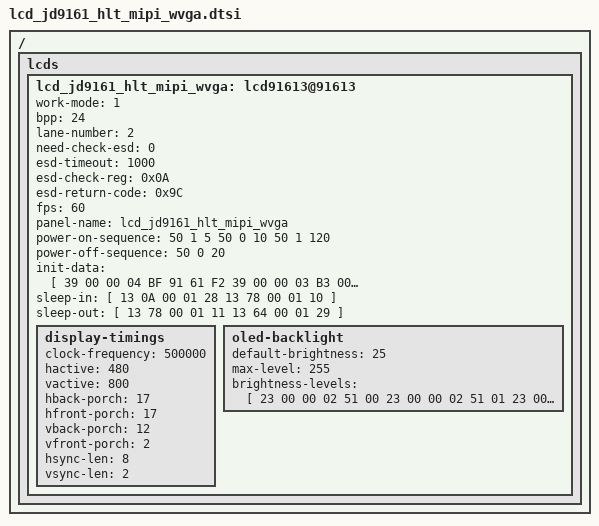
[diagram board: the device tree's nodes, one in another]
/ { lcds {
	lcd_jd9161_hlt_mipi_wvga: lcd91613@91613 {

		work-mode = <1>;
		bpp = <24>;
		lane-number = <2>;
		need-check-esd = <0>;
		esd-timeout = <1000>;
		esd-check-reg = <0x0A>;
		esd-return-code = <0x9C>;
		fps = <60>;
		panel-name = "lcd_jd9161_hlt_mipi_wvga";
		power-on-sequence = <
					50  1  5
					50  0  10
					50  1  120
					>;
		power-off-sequence = <
					50  0  20
					>;
		init-data = [
			39 00 00 04 BF 91 61 F2
			39 00 00 03 B3 00 BD
			39 00 00 03 B4 00 BF
			39 00 00 07 B8 00 BF 01 00 BF 01
			39 00 00 04 BA 3E 23 00
			23 78 00 02 C3 02
			39 00 00 03 C4 00 64
			39 00 00 27 C8 7F 78 68 5A 49 34 34 1C 37 38 3B 5E 52 63 5C 64 5E 58 4E 7F 78 68 5A 49 34 34 1C 37 38 3B 5E 52 63 5C 64 5E 58 4E
			39 00 00 0A C7 00 01 32 05 65 2B 12 A5 A5
			39 00 00 11 D4 1E 1F 17 37 06 04 0A 08 00 02 1F 1F 1F 1F 1F 1F
			39 00 00 11 D5 1E 1F 17 37 07 05 0B 09 01 03 1F 1F 1F 1F 1F 1F
			39 00 00 11 D6 1F 1E 17 17 07 09 0B 05 03 01 1F 1F 1F 1F 1F 1F
			39 00 00 11 D7 1F 1E 17 17 06 08 0A 04 02 00 1F 1F 1F 1F 1F 1F
			39 00 00 15 D8 20 00 00 30 03 30 01 02 00 01 02 06 70 00 00 73 07 06 70 08
			39 00 00 14 D9 00 0A 0A 80 00 00 06 7B 00 80 00 33 6A 1F 00 00 00 03 7B
			23 05 00 02 53 2c
			23 05 00 02 55 01
			23 05 00 02 51 00
			13 78 00 01 11
			13 0A 00 01 29
			];
		sleep-in = [
			13 0A 00 01 28
			13 78 00 01 10
			];
		sleep-out = [
			13 78 00 01 11
			13 64 00 01 29
			];
		display-timings {
			clock-frequency = <500000>;
			hactive = <480>;
			vactive = <800>;
			hback-porch = <17>;
			hfront-porch = <17>;
			vback-porch = <12>;
			vfront-porch = <2>;
			hsync-len = <8>;
			vsync-len = <2>;
		};
		oled-backlight {
			default-brightness = <25>;
			max-level = <255>;
			brightness-levels = [
				23 00 00 02 51 00
				23 00 00 02 51 01
				23 00 00 02 51 02
				23 00 00 02 51 03
				23 00 00 02 51 04
				23 00 00 02 51 05
				23 00 00 02 51 06
				23 00 00 02 51 07
				23 00 00 02 51 08
				23 00 00 02 51 09
				23 00 00 02 51 0A
				23 00 00 02 51 0A
				23 00 00 02 51 0B
				23 00 00 02 51 0B
				23 00 00 02 51 0C
				23 00 00 02 51 0C
				23 00 00 02 51 0D
				23 00 00 02 51 0D
				23 00 00 02 51 0E
				23 00 00 02 51 0E
				23 00 00 02 51 0F
				23 00 00 02 51 0F
				23 00 00 02 51 10
				23 00 00 02 51 11
				23 00 00 02 51 11
				23 00 00 02 51 12
				23 00 00 02 51 12
				23 00 00 02 51 13
				23 00 00 02 51 13
				23 00 00 02 51 14
				23 00 00 02 51 14
				23 00 00 02 51 15
				23 00 00 02 51 15
				23 00 00 02 51 16
				23 00 00 02 51 17
				23 00 00 02 51 17
				23 00 00 02 51 18
				23 00 00 02 51 18
				23 00 00 02 51 19
				23 00 00 02 51 19
				23 00 00 02 51 1A
				23 00 00 02 51 1A
				23 00 00 02 51 1B
				23 00 00 02 51 1B
				23 00 00 02 51 1C
				23 00 00 02 51 1D
				23 00 00 02 51 1D
				23 00 00 02 51 1E
				23 00 00 02 51 1E
				23 00 00 02 51 1F
				23 00 00 02 51 1F
				23 00 00 02 51 20
				23 00 00 02 51 20
				23 00 00 02 51 21
				23 00 00 02 51 21
				23 00 00 02 51 22
				23 00 00 02 51 23
				23 00 00 02 51 23
				23 00 00 02 51 24
				23 00 00 02 51 24
				23 00 00 02 51 25
				23 00 00 02 51 25
				23 00 00 02 51 26
				23 00 00 02 51 26
				23 00 00 02 51 27
				23 00 00 02 51 27
				23 00 00 02 51 28
				23 00 00 02 51 28
				23 00 00 02 51 29
				23 00 00 02 51 2A
				23 00 00 02 51 2A
				23 00 00 02 51 2B
				23 00 00 02 51 2B
				23 00 00 02 51 2C
				23 00 00 02 51 2C
				23 00 00 02 51 2D
				23 00 00 02 51 2D
				23 00 00 02 51 2E
				23 00 00 02 51 2E
				23 00 00 02 51 2F
				23 00 00 02 51 30
				23 00 00 02 51 30
				23 00 00 02 51 31
				23 00 00 02 51 31
				23 00 00 02 51 32
				23 00 00 02 51 32
				23 00 00 02 51 33
				23 00 00 02 51 33
				23 00 00 02 51 34
				23 00 00 02 51 34
				23 00 00 02 51 35
				23 00 00 02 51 36
				23 00 00 02 51 36
				23 00 00 02 51 37
				23 00 00 02 51 37
				23 00 00 02 51 38
				23 00 00 02 51 38
				23 00 00 02 51 39
				23 00 00 02 51 39
				23 00 00 02 51 3A
				23 00 00 02 51 3A
				23 00 00 02 51 3B
				23 00 00 02 51 3C
				23 00 00 02 51 3C
				23 00 00 02 51 3C
				23 00 00 02 51 3D
				23 00 00 02 51 3D
				23 00 00 02 51 3D
				23 00 00 02 51 3E
				23 00 00 02 51 3E
				23 00 00 02 51 3F
				23 00 00 02 51 3F
				23 00 00 02 51 3F
				23 00 00 02 51 40
				23 00 00 02 51 40
				23 00 00 02 51 41
				23 00 00 02 51 41
				23 00 00 02 51 41
				23 00 00 02 51 42
				23 00 00 02 51 42
				23 00 00 02 51 43
				23 00 00 02 51 43
				23 00 00 02 51 43
				23 00 00 02 51 44
				23 00 00 02 51 44
				23 00 00 02 51 45
				23 00 00 02 51 45
				23 00 00 02 51 46
				23 00 00 02 51 46
				23 00 00 02 51 47
				23 00 00 02 51 48
				23 00 00 02 51 49
				23 00 00 02 51 4A
				23 00 00 02 51 4B
				23 00 00 02 51 4C
				23 00 00 02 51 4C
				23 00 00 02 51 4D
				23 00 00 02 51 4E
				23 00 00 02 51 4F
				23 00 00 02 51 50
				23 00 00 02 51 51
				23 00 00 02 51 52
				23 00 00 02 51 52
				23 00 00 02 51 53
				23 00 00 02 51 54
				23 00 00 02 51 55
				23 00 00 02 51 56
				23 00 00 02 51 57
				23 00 00 02 51 58
				23 00 00 02 51 58
				23 00 00 02 51 59
				23 00 00 02 51 5A
				23 00 00 02 51 5B
				23 00 00 02 51 5C
				23 00 00 02 51 5D
				23 00 00 02 51 5E
				23 00 00 02 51 5E
				23 00 00 02 51 5F
				23 00 00 02 51 60
				23 00 00 02 51 61
				23 00 00 02 51 62
				23 00 00 02 51 63
				23 00 00 02 51 64
				23 00 00 02 51 64
				23 00 00 02 51 65
				23 00 00 02 51 66
				23 00 00 02 51 67
				23 00 00 02 51 68
				23 00 00 02 51 69
				23 00 00 02 51 6A
				23 00 00 02 51 6A
				23 00 00 02 51 6B
				23 00 00 02 51 6C
				23 00 00 02 51 6D
				23 00 00 02 51 6E
				23 00 00 02 51 6F
				23 00 00 02 51 70
				23 00 00 02 51 70
				23 00 00 02 51 71
				23 00 00 02 51 72
				23 00 00 02 51 73
				23 00 00 02 51 74
				23 00 00 02 51 75
				23 00 00 02 51 76
				23 00 00 02 51 76
				23 00 00 02 51 77
				23 00 00 02 51 78
				23 00 00 02 51 79
				23 00 00 02 51 7A
				23 00 00 02 51 7B
				23 00 00 02 51 7C
				23 00 00 02 51 7C
				23 00 00 02 51 7D
				23 00 00 02 51 7E
				23 00 00 02 51 7F
				23 00 00 02 51 80
				23 00 00 02 51 81
				23 00 00 02 51 82
				23 00 00 02 51 83
				23 00 00 02 51 83
				23 00 00 02 51 84
				23 00 00 02 51 85
				23 00 00 02 51 86
				23 00 00 02 51 87
				23 00 00 02 51 88
				23 00 00 02 51 89
				23 00 00 02 51 89
				23 00 00 02 51 8A
				23 00 00 02 51 8B
				23 00 00 02 51 8C
				23 00 00 02 51 8D
				23 00 00 02 51 8E
				23 00 00 02 51 8F
				23 00 00 02 51 8F
				23 00 00 02 51 90
				23 00 00 02 51 91
				23 00 00 02 51 92
				23 00 00 02 51 93
				23 00 00 02 51 94
				23 00 00 02 51 95
				23 00 00 02 51 95
				23 00 00 02 51 96
				23 00 00 02 51 97
				23 00 00 02 51 98
				23 00 00 02 51 99
				23 00 00 02 51 9A
				23 00 00 02 51 9B
				23 00 00 02 51 9B
				23 00 00 02 51 9C
				23 00 00 02 51 9D
				23 00 00 02 51 9E
				23 00 00 02 51 9F
				23 00 00 02 51 A0
				23 00 00 02 51 A1
				23 00 00 02 51 A1
				23 00 00 02 51 A2
				23 00 00 02 51 A3
				23 00 00 02 51 A4
				23 00 00 02 51 A5
				23 00 00 02 51 A6
				23 00 00 02 51 A7
				23 00 00 02 51 A7
				23 00 00 02 51 A8
				23 00 00 02 51 A9
				23 00 00 02 51 AA
				23 00 00 02 51 AB
				23 00 00 02 51 AC
				23 00 00 02 51 AD
				23 00 00 02 51 AD
				23 00 00 02 51 AE
				23 00 00 02 51 AF
				23 00 00 02 51 B0
				23 00 00 02 51 B1
				23 00 00 02 51 B2
				23 00 00 02 51 B3
				23 00 00 02 51 B4
			];
		};
	};
};};

